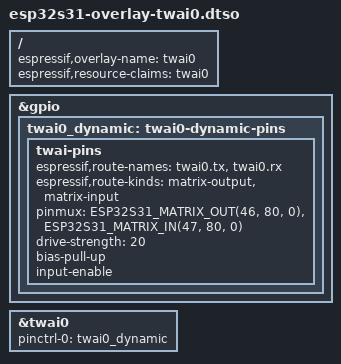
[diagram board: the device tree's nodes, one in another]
// SPDX-License-Identifier: GPL-2.0+
/dts-v1/;
/plugin/;

#include <dt-bindings/pinctrl/esp32s31-pinmux.h>

/ {
	espressif,overlay-name = "twai0";
	espressif,resource-claims = "twai0";
};

&gpio {
	twai0_dynamic: twai0-dynamic-pins {
		twai-pins {
			espressif,route-names = "twai0.tx", "twai0.rx";
			espressif,route-kinds = "matrix-output", "matrix-input";
			pinmux = <ESP32S31_MATRIX_OUT(46, 80, 0)>,
				 <ESP32S31_MATRIX_IN(47, 80, 0)>;
			drive-strength = <20>;
			bias-pull-up;
			input-enable;
		};
	};
};

&twai0 {
	pinctrl-0 = <&twai0_dynamic>;
	status = "okay";
};
